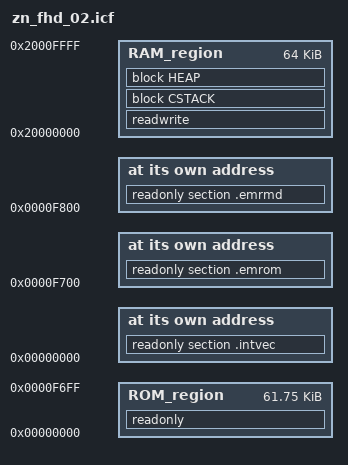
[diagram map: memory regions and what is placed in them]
/*###ICF### Section handled by ICF editor, don't touch! ****/
/*-Editor annotation file-*/
/* IcfEditorFile="$TOOLKIT_DIR$\config\ide\IcfEditor\cortex_v1_0.xml" */
/*-Specials-*/
define symbol __ICFEDIT_intvec_start__ = 0x00000000;
/*-Memory Regions-*/
define symbol __ICFEDIT_region_ROM_start__   = 0x00000000;
define symbol __ICFEDIT_region_ROM_end__     = 0x0000F6FF;
define symbol MY_ROM_START=0x0F700; 
define symbol MY_ROM_END=0x0FFFF; 
define symbol MY_ROM_S2=0x0F800; 
define symbol __ICFEDIT_region_RAM_start__   = 0x20000000;
define symbol __ICFEDIT_region_RAM_end__     = 0x2000FFFF;
/*-Sizes-*/
define symbol __ICFEDIT_size_cstack__   = 0x400;
define symbol __ICFEDIT_size_heap__     = 0x800;
/**** End of ICF editor section. ###ICF###*/


define memory mem with size = 4G;
define region ROM_region   = mem:[from __ICFEDIT_region_ROM_start__   to __ICFEDIT_region_ROM_end__];
define region RAM_region   = mem:[from __ICFEDIT_region_RAM_start__   to __ICFEDIT_region_RAM_end__];
//define region MY_ROM       = mem:[from MY_ROM_START   to MY_ROM_END];
define block CSTACK    with alignment = 8, size = __ICFEDIT_size_cstack__   { };
define block HEAP      with alignment = 8, size = __ICFEDIT_size_heap__     { };

initialize by copy { readwrite };
//initialize by copy with packing = none { section __DLIB_PERTHREAD }; // Required in a multi-threaded application
do not initialize  { section .noinit };

place at address mem:__ICFEDIT_intvec_start__ { readonly section .intvec };
place at address mem:MY_ROM_START {  readonly section .emrom };
place at address mem:MY_ROM_S2 {  readonly section .emrmd };
place in ROM_region   { readonly };
place in RAM_region   { readwrite,
                        block CSTACK, block HEAP };
//place in  MY_ROM   { ro data};
